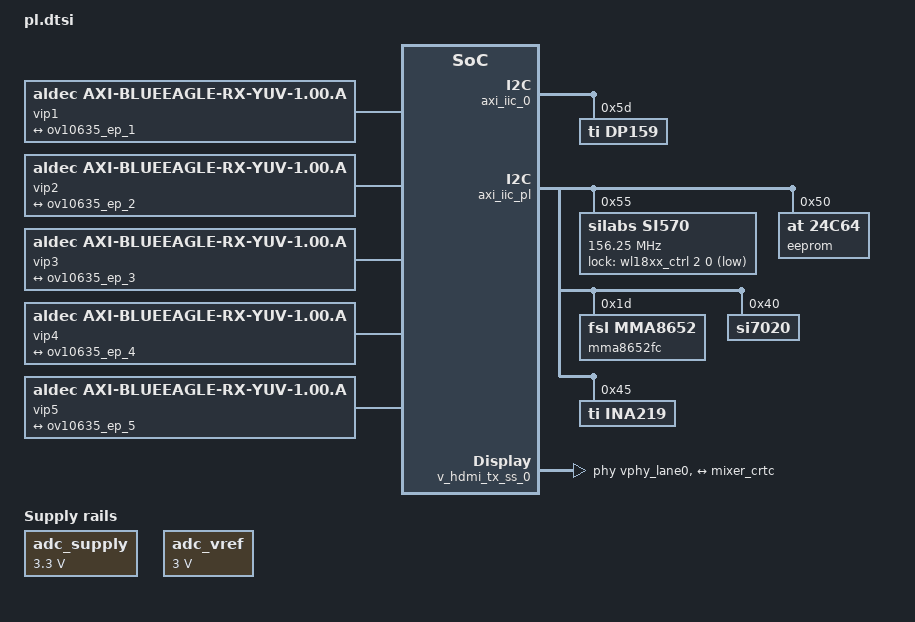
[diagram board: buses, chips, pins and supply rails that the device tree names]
/*
 * CAUTION: This file is automatically generated by Xilinx.
 * Version: XSCT 2018.3
 * Today is: Fri Feb  1 14:32:24 2019
 */


/ {
	amba_pl: amba_pl@0 {
		#address-cells = <2>;
		#size-cells = <2>;
		compatible = "simple-bus";
		ranges ;
		axi_gpio_des: gpio@a0001000 {
			#gpio-cells = <3>;
			clock-names = "s_axi_aclk";
			clocks = <&misc_clk_0>;
			compatible = "xlnx,axi-gpio-2.0", "xlnx,xps-gpio-1.00.a";
			gpio-controller ;
			reg = <0x0 0xa0001000 0x0 0x1000>;
			xlnx,all-inputs = <0x0>;
			xlnx,all-inputs-2 = <0x0>;
			xlnx,all-outputs = <0x1>;
			xlnx,all-outputs-2 = <0x0>;
			xlnx,dout-default = <0x0000000E>;
			xlnx,dout-default-2 = <0x00000000>;
			xlnx,gpio-width = <0x4>;
			xlnx,gpio2-width = <0x20>;
			xlnx,interrupt-present = <0x0>;
			xlnx,is-dual = <0x0>;
			xlnx,tri-default = <0xFFFFFFFF>;
			xlnx,tri-default-2 = <0xFFFFFFFF>;
		};        
		gpio-pdb {
		    compatible = "linux,gpio-reset";

		    multides {
		        // Put PDB line low for a 1 ms during bootup
		        gpios = <&axi_gpio_des 1 0 0>;
		        asserted-state = <0>;
		        duration-ms = <1>;
		        auto;
		    };
		};
		axi_gpio_ov_ctrl: gpio@a0004000 {
			#gpio-cells = <3>;
			clock-names = "s_axi_aclk";
			clocks = <&misc_clk_0>;
			compatible = "xlnx,axi-gpio-2.0", "xlnx,xps-gpio-1.00.a";
			gpio-controller ;
			reg = <0x0 0xa0004000 0x0 0x1000>;
			xlnx,all-inputs = <0x0>;
			xlnx,all-inputs-2 = <0x0>;
			xlnx,all-outputs = <0x1>;
			xlnx,all-outputs-2 = <0x0>;
			xlnx,dout-default = <0x00000155>;
			xlnx,dout-default-2 = <0x00000000>;
			xlnx,gpio-width = <0xa>;
			xlnx,gpio2-width = <0x20>;
			xlnx,interrupt-present = <0x0>;
			xlnx,is-dual = <0x0>;
			xlnx,tri-default = <0xFFFFFFFF>;
			xlnx,tri-default-2 = <0xFFFFFFFF>;
		};
		axi_iic_0: i2c@a000b000 {
			#address-cells = <1>;
			#size-cells = <0>;
			clock-names = "s_axi_aclk";
			clocks = <&misc_clk_0>;
			compatible = "xlnx,axi-iic-2.0", "xlnx,xps-iic-2.00.a";
			interrupt-names = "iic2intc_irpt";
			interrupt-parent = <&axi_intc_0>;
			interrupts = <9 2>;
			reg = <0x0 0xa000b000 0x0 0x1000>;
			dp159: hdmi-retimer@5d {
					status = "okay";
					compatible = "ti,dp159";
					reg = <0x5d>;
					#address-cells = <1>;
					#size-cells = <0>;
					#clock-cells = <0>;
				};
		};
		axi_iic_pl: i2c@a0003000 {
			#address-cells = <1>;
			#size-cells = <0>;
			clock-names = "s_axi_aclk";
			clocks = <&misc_clk_0>;
			compatible = "xlnx,axi-iic-2.0", "xlnx,xps-iic-2.00.a";
			interrupt-names = "iic2intc_irpt";
			interrupt-parent = <&axi_intc_0>;
			interrupts = <0 2>;
			reg = <0x0 0xa0003000 0x0 0x1000>;
			
			si570: clock-generator@55 {
				#clock-cells = <0>;
				compatible = "silabs,si570";
				reg = <0x55>;
				temperature-stability = <50>;
				factory-fout = <156250000>;
				clock-frequency = <156250000>;
				lock-gpios = <&wl18xx_ctrl 2 0 1>;
			};
				
			
			eeprom@50 {
				compatible = "at,24c64";
				reg = <0x50>;
			};
			
			/* DNI */
			mma8652fc@1d {
				compatible = "fsl,mma8652";
				reg = <0x1d>;
			};
			
			si7020@40 {
				compatible = "si7020";
				reg = <0x40>;
			};
			
			ina219@45 {
				compatible = "ti,ina219";
				reg = <0x45>;
				shunt-resistor = <2000>;
			};
		};
		axi_intc_0: interrupt-controller@a000a000 {
			#interrupt-cells = <2>;
			compatible = "xlnx,axi-intc-4.1", "xlnx,xps-intc-1.00.a";
			interrupt-controller ;
			interrupt-names = "irq";
			interrupt-parent = <&gic>;
			interrupts = <0 89 4>;
			reg = <0x0 0xa000a000 0x0 0x1000>;
			xlnx,kind-of-intr = <0x0>;
			xlnx,num-intr-inputs = <0xa>;
		};
		
		adc_supply: fixedregulator-vcc {
			compatible = "regulator-fixed";
			regulator-name = "fixed-supply";
			regulator-min-microvolt = <3300000>;
			regulator-max-microvolt = <3300000>;
		};

		adc_vref: fixedregulator-refin {
			compatible = "regulator-fixed";
			regulator-name = "fixed-supply";
			regulator-min-microvolt = <3000000>;
			regulator-max-microvolt = <3000000>;
		};
		axi_timer_0: timer@a0009000 {
			clock-frequency = <50000000>;
			clock-names = "s_axi_aclk";
			clocks = <&misc_clk_0>;
			#pwm-cells = <1>;
			compatible = "xlnx,axi-timer-2.0";
			xlnx,pwm-outputs = <1>;
			reg = <0x0 0xa0009000 0x0 0x1000>;
			xlnx,count-width = <0x20>;
			xlnx,gen0-assert = <0x1>;
			xlnx,gen1-assert = <0x1>;
			xlnx,one-timer-only = <0x0>;
			xlnx,trig0-assert = <0x1>;
			xlnx,trig1-assert = <0x1>;
		};
		nidru: nidru {
			compatible = "fixed-clock";
			#clock-cells = <0x0>;
			clock-frequency = <156250000>;
		};
		psu_ctrl_ipi: PERIPHERAL@ff380000 {
			/* This is a place holder node for a custom IP, user may need to update the entries */
			compatible = "xlnx,PERIPHERAL-1.0";
			reg = <0x0 0xff380000 0x0 0x80000>;
		};
		psu_message_buffers: PERIPHERAL@ff990000 {
			/* This is a place holder node for a custom IP, user may need to update the entries */
			compatible = "xlnx,PERIPHERAL-1.0";
			reg = <0x0 0xff990000 0x0 0x10000>;
		};
		v_hdmi_tx_ss_0: v_hdmi_tx_ss@a0020000 {
			/* This is a place holder node for a custom IP, user may need to update the entries */
			compatible = "xlnx,v-hdmi-tx-ss-3.1";

			interrupt-names = "irq";
			interrupt-parent = <&axi_intc_0>;
			interrupts = <7 2>;

			reg = <0x0 0xa0020000 0x0 0x20000>;

			clocks = <&misc_clk_0>, <&misc_clk_1>, <&si570>, <&dp159>;
			clock-names = "axi-lite", "video", "txref-clk", "retimer-clk";

			phy-names = "hdmi-phy0", "hdmi-phy1", "hdmi-phy2";
			phys = <&vphy_lane0 0 1 1 1>, <&vphy_lane1 0 1 1 1>, <&vphy_lane2 0 1 1 1>;

			/*xlnx,add-mark-dbg = "false";
			xlnx,addr-width = <0xa>;
			xlnx,exdes-axilite-freq = <0x64>;
			xlnx,exdes-nidru = "false";
			xlnx,exdes-rx-pll-selection = <0x0>;
			xlnx,exdes-topology = <0x1>;
			xlnx,exdes-tx-pll-selection = <0x6>;
			xlnx,hdmi-fast-switch = "false";
			xlnx,hdmi-version = <0x3>;
			xlnx,hpd-invert = "false";
			xlnx,hysteresis-level = <0xc>;
			xlnx,include-hdcp-1-4 = "false";
			xlnx,include-hdcp-2-2 = "false";
			xlnx,include-low-reso-vid = "false";
			xlnx,include-yuv420-sup = "true";
			xlnx,input-pixels-per-clock = <0x2>;
			xlnx,max-bits-per-component = <0x8>;
			xlnx,validation-enable = "false";
			xlnx,vid-interface = <0x0>;
			xlnx,video-mask-enable = <0x1>;*/

			xlnx,output-fmt = "rgb";
			xlnx,input-pixels-per-clock = <0x2>;
			xlnx,max-bits-per-component = <0x8>;
			
			ports {
				#address-cells = <1>;
				#size-cells = <0>;
				encoder_hdmi_port: port@0 {
					reg = <0>;
					hdmi_encoder: endpoint {
						remote-endpoint = <&mixer_crtc>;
					};
				};
			};
		};
		v_mix_0: v_mix@b0010000 {
			/* This is a place holder node for a custom IP, user may need to update the entries */
			compatible = "xlnx,v-mix-3.0", "xlnx,mixer-3.0";
			interrupt-names = "interrupt";
			interrupt-parent = <&axi_intc_0>;
			interrupts = <6 2>;
			reg = <0x0 0xb0010000 0x0 0x10000>;
			xlnx,s-axi-ctrl-addr-width = <0xc>;
			xlnx,s-axi-ctrl-data-width = <0x20>;
			reset-gpios = <&gpio 79 1>;
			clocks = <&si570>;
			xlnx,connector-type = "HDMIA";
			xlnx,dma-addr-width=<32>;

			xlnx,bpc = <8>;
			xlnx,ppc = <2>;
			xlnx,num-layers = <5>;

			crtc_mixer_port: port@0 {
					reg = <0>;
					mixer_crtc: endpoint {
					remote-endpoint = <&hdmi_encoder>;
				};
			};

			mixer_master_layer: layer_0 {
				xlnx,layer-id = <0>;
				xlnx,layer-max-width = <3840>;
				xlnx,layer-max-height = <2160>;
				xlnx,vformat = "BG24";
			};
			mixer_overlay_1: layer_1 {
				xlnx,layer-id = <1>;
				xlnx,vformat = "YUYV";
				xlnx,layer-alpha;
				xlnx,layer-max-width = <3840>;
			};
			mixer_overlay_2: layer_2 {
				xlnx,layer-id = <2>;
				xlnx,vformat = "YUYV";
				xlnx,layer-alpha;
				xlnx,layer-max-width = <3840>;
			};
			mixer_overlay_3: layer_3 {
				xlnx,layer-id = <3>;
				xlnx,vformat = "UYVY";
				xlnx,layer-alpha;
				xlnx,layer-max-width = <3840>;
			};
			mixer_overlay_4: layer_4 {
				xlnx,layer-id = <4>;
				xlnx,vformat = "AR24";
				xlnx,layer-alpha;
				xlnx,layer-max-width = <3840>;
				xlnx,layer-primary;
			};
			xv_mix_logo: logo {
				xlnx,layer-id = <5>;
				xlnx,logo-height = <64>;
				xlnx,logo-width = <64>;
			};
		};
		vid_phy_controller_0: vid_phy_controller@a0060000 {
			/* This is a place holder node for a custom IP, user may need to update the entries */
			compatible = "xlnx,vid-phy-controller-2.2";
			interrupt-names = "irq";
			interrupt-parent = <&axi_intc_0>;
			interrupts = <8 2>;
			reg = <0x0 0xa0060000 0x0 0x10000>;
			clocks = <&misc_clk_0>, <&nidru>;
			clock-names = "axi-lite", "dru-clk";
			xlnx,axi4lite-enable = "true";
			xlnx,component-name = "TySOM_3_ZU7_FMC1_FMC_ADAS_vid_phy_controller_0_0";
			xlnx,device = "xczu7ev";
			xlnx,dru-gain-g1 = <0x9>;
			xlnx,dru-gain-g1-p = <0x10>;
			xlnx,dru-gain-g2 = <0x4>;
			xlnx,dru-refclk-fabric-buffer = "none";
			xlnx,err-irq-en = <0x0>;
			xlnx,for-upgrade-architecture = "placeholder";
			xlnx,for-upgrade-device = "placeholder";
			xlnx,for-upgrade-maxoptvol = "0.00";
			xlnx,for-upgrade-package = "placeholder";
			xlnx,for-upgrade-part = "placeholder";
			xlnx,for-upgrade-refvol = "0.00";
			xlnx,for-upgrade-speedgrade = <0x0>;
			xlnx,hdmi-fast-switch = <0x1>;
			xlnx,input-pixels-per-clock = <0x2>;
			xlnx,int-hdmi-ver-cmptble = <0x3>;
			xlnx,nidru = <0x0>;
			xlnx,nidru-refclk-sel = <0x0>;
			xlnx,rx-gt-debug-ports = "false";
			xlnx,rx-no-of-channels = <0x3>;
			xlnx,rx-outclk-buffer = "none";
			xlnx,rx-pll-selection = <0x0>;
			xlnx,rx-protocol = <0x3>;
			xlnx,rx-raw-mode-en = "false";
			xlnx,rx-refclk-sel = <0x1>;
			xlnx,rx-sb-ports = "true";
			xlnx,rx-tmds-clk-buffer = "bufg";
			xlnx,rx-video-clk-buffer = "bufg";
			xlnx,silicon-revision = <0x0>;
			xlnx,speedgrade = "-2";
			xlnx,supportlevel = <0x1>;
			xlnx,transceivercontrol = "false";
			xlnx,tx-gt-debug-ports = "false";
			xlnx,tx-no-of-channels = <0x3>;
			xlnx,tx-outclk-buffer = "none";
			xlnx,tx-pll-selection = <0x6>;
			xlnx,tx-protocol = <0x1>;
			xlnx,tx-raw-mode-en = "false";
			xlnx,tx-refclk-fabric-buffer = "none";
			xlnx,tx-refclk-sel = <0x0>;
			xlnx,tx-sb-ports = "true";
			xlnx,tx-tmds-clk-buffer = "bufg";
			xlnx,tx-video-clk-buffer = "bufg";
			xlnx,txpi-port-en = "false";
			xlnx,txrefclk-rdy-invert = <0x1>;
			xlnx,use-gt-ch4-hdmi = <0x0>;
			xlnx,use-oddr-for-tmds-clkout = "true";
			xlnx,vid-phy-axi4lite-addr-width = <0xa>;
			xlnx,vid-phy-axi4lite-data-width = <0x20>;
			xlnx,vid-phy-control-sb-rx-tdata-width = <0x1>;
			xlnx,vid-phy-control-sb-tx-tdata-width = <0x1>;
			xlnx,vid-phy-rx-axi4s-ch-int-tdata-width = <0x14>;
			xlnx,vid-phy-rx-axi4s-ch-tdata-width = <0x14>;
			xlnx,vid-phy-rx-axi4s-ch-tuser-width = <0x1>;
			xlnx,vid-phy-status-sb-rx-tdata-width = <0x1>;
			xlnx,vid-phy-status-sb-tx-tdata-width = <0x2>;
			xlnx,vid-phy-tx-axi4s-ch-int-tdata-width = <0x14>;
			xlnx,vid-phy-tx-axi4s-ch-tdata-width = <0x14>;
			xlnx,vid-phy-tx-axi4s-ch-tuser-width = <0x1>;
			xlnx,viper-reg = "false";
			xlnx,transceiver-type = <0x5>;
			xlnx,tx-buffer-bypass = <0x1>;
			xlnx,transceiver-width = <2>;
			vphy_lane0: vphy_lane@0 {
				#phy-cells = <4>;
			};
			vphy_lane1: vphy_lane@1 {
				#phy-cells = <4>;
			};
			vphy_lane2: vphy_lane@2 {
				#phy-cells = <4>;
			};
			vphy_lane3: vphy_lane@3 {
				#phy-cells = <4>;
			};
		};
		vip1_axi_vdma_des1: dma@a0000000 {
			#dma-cells = <1>;
			clock-names = "s_axi_lite_aclk", "m_axi_s2mm_aclk", "s_axis_s2mm_aclk";
			clocks = <&misc_clk_0>, <&misc_clk_0>, <&misc_clk_0>;
			compatible = "xlnx,axi-vdma-6.3", "xlnx,axi-vdma-1.00.a";
			interrupt-names = "s2mm_introut";
			interrupt-parent = <&axi_intc_0>;
			interrupts = <1 2>;
			reg = <0x0 0xa0000000 0x0 0x1000>;
			xlnx,addrwidth = <0x20>;
			xlnx,flush-fsync = <0x1>;
			xlnx,num-fstores = <0x3>;
			dma-channel@a0000030 {
				compatible = "xlnx,axi-vdma-s2mm-channel";
				interrupts = <1 2>;
				xlnx,datawidth = <0x10>;
				xlnx,device-id = <0x0>;
				xlnx,genlock-mode ;
			};
		};
		vip2_axi_vdma_des2: dma@a0005000 {
			#dma-cells = <1>;
			clock-names = "s_axi_lite_aclk", "m_axi_s2mm_aclk", "s_axis_s2mm_aclk";
			clocks = <&misc_clk_0>, <&misc_clk_0>, <&misc_clk_0>;
			compatible = "xlnx,axi-vdma-6.3", "xlnx,axi-vdma-1.00.a";
			interrupt-names = "s2mm_introut";
			interrupt-parent = <&axi_intc_0>;
			interrupts = <2 2>;
			reg = <0x0 0xa0005000 0x0 0x1000>;
			xlnx,addrwidth = <0x20>;
			xlnx,flush-fsync = <0x1>;
			xlnx,num-fstores = <0x3>;
			dma-channel@a0005030 {
				compatible = "xlnx,axi-vdma-s2mm-channel";
				interrupts = <2 2>;
				xlnx,datawidth = <0x10>;
				xlnx,device-id = <0x1>;
				xlnx,genlock-mode ;
			};
		};
		vip3_axi_vdma_des3: dma@a0006000 {
			#dma-cells = <1>;
			clock-names = "s_axi_lite_aclk", "m_axi_s2mm_aclk", "s_axis_s2mm_aclk";
			clocks = <&misc_clk_0>, <&misc_clk_0>, <&misc_clk_0>;
			compatible = "xlnx,axi-vdma-6.3", "xlnx,axi-vdma-1.00.a";
			interrupt-names = "s2mm_introut";
			interrupt-parent = <&axi_intc_0>;
			interrupts = <3 2>;
			reg = <0x0 0xa0006000 0x0 0x1000>;
			xlnx,addrwidth = <0x20>;
			xlnx,flush-fsync = <0x1>;
			xlnx,num-fstores = <0x3>;
			dma-channel@a0006030 {
				compatible = "xlnx,axi-vdma-s2mm-channel";
				interrupts = <3 2>;
				xlnx,datawidth = <0x10>;
				xlnx,device-id = <0x2>;
				xlnx,genlock-mode ;
			};
		};
		vip4_axi_vdma_des4: dma@a0007000 {
			#dma-cells = <1>;
			clock-names = "s_axi_lite_aclk", "m_axi_s2mm_aclk", "s_axis_s2mm_aclk";
			clocks = <&misc_clk_0>, <&misc_clk_0>, <&misc_clk_0>;
			compatible = "xlnx,axi-vdma-6.3", "xlnx,axi-vdma-1.00.a";
			interrupt-names = "s2mm_introut";
			interrupt-parent = <&axi_intc_0>;
			interrupts = <4 2>;
			reg = <0x0 0xa0007000 0x0 0x1000>;
			xlnx,addrwidth = <0x20>;
			xlnx,flush-fsync = <0x1>;
			xlnx,num-fstores = <0x3>;
			dma-channel@a0007030 {
				compatible = "xlnx,axi-vdma-s2mm-channel";
				interrupts = <4 2>;
				xlnx,datawidth = <0x10>;
				xlnx,device-id = <0x3>;
				xlnx,genlock-mode ;
			};
		};
		vip5_axi_vdma_des5: dma@a0008000 {
			#dma-cells = <1>;
			clock-names = "s_axi_lite_aclk", "m_axi_s2mm_aclk", "s_axis_s2mm_aclk";
			clocks = <&misc_clk_0>, <&misc_clk_0>, <&misc_clk_0>;
			compatible = "xlnx,axi-vdma-6.3", "xlnx,axi-vdma-1.00.a";
			interrupt-names = "s2mm_introut";
			interrupt-parent = <&axi_intc_0>;
			interrupts = <5 2>;
			reg = <0x0 0xa0008000 0x0 0x1000>;
			xlnx,addrwidth = <0x20>;
			xlnx,flush-fsync = <0x1>;
			xlnx,num-fstores = <0x3>;
			dma-channel@a0008030 {
				compatible = "xlnx,axi-vdma-s2mm-channel";
				interrupts = <5 2>;
				xlnx,datawidth = <0x10>;
				xlnx,device-id = <0x4>;
				xlnx,genlock-mode ;
			};
		};
		
		vip1 {
			compatible = "aldec,axi-blueeagle-rx-yuv-1.00.a";

			dmas = <&vip1_axi_vdma_des1 0>;
			dma-names = "video";

			port {
				vip_ep_1: endpoint {
					remote-endpoint = <&ov10635_ep_1>;
				};
			};
		};
		
		vip2 {
			compatible = "aldec,axi-blueeagle-rx-yuv-1.00.a";

			dmas = <&vip2_axi_vdma_des2 0>;
			dma-names = "video";

			port {
				vip_ep_2: endpoint {
					remote-endpoint = <&ov10635_ep_2>;
				};
			};
		};
		
		vip3 {
			compatible = "aldec,axi-blueeagle-rx-yuv-1.00.a";

			dmas = <&vip3_axi_vdma_des3 0>;
			dma-names = "video";

			port {
				vip_ep_3: endpoint {
					remote-endpoint = <&ov10635_ep_3>;
				};
			};
		};
		
		vip4 {
			compatible = "aldec,axi-blueeagle-rx-yuv-1.00.a";

			dmas = <&vip4_axi_vdma_des4 0>;
			dma-names = "video";

			port {
				vip_ep_4: endpoint {
					remote-endpoint = <&ov10635_ep_4>;
				};
			};
		};
		
		vip5 {
			compatible = "aldec,axi-blueeagle-rx-yuv-1.00.a";

			dmas = <&vip5_axi_vdma_des5 0>;
			dma-names = "video";

			port {
				vip_ep_5: endpoint {
					remote-endpoint = <&ov10635_ep_5>;
				};
			};
		};
		wl18xx_ctrl: gpio@a0002000 {
			#gpio-cells = <3>;
			clock-names = "s_axi_aclk";
			clocks = <&misc_clk_0>;
			compatible = "xlnx,axi-gpio-2.0", "xlnx,xps-gpio-1.00.a";
			gpio-controller ;
			reg = <0x0 0xa0002000 0x0 0x1000>;
			xlnx,all-inputs = <0x0>;
			xlnx,all-inputs-2 = <0x0>;
			xlnx,all-outputs = <0x1>;
			xlnx,all-outputs-2 = <0x0>;
			xlnx,dout-default = <0x00000000>;
			xlnx,dout-default-2 = <0x00000000>;
			xlnx,gpio-width = <0x3>;
			xlnx,gpio2-width = <0x20>;
			xlnx,interrupt-present = <0x0>;
			xlnx,is-dual = <0x0>;
			xlnx,tri-default = <0xFFFFFFFF>;
			xlnx,tri-default-2 = <0xFFFFFFFF>;
		};
		misc_clk_0: misc_clk_0 {
			#clock-cells = <0>;
			clock-frequency = <50000000>;
			compatible = "fixed-clock";
		};
		misc_clk_1: misc_clk_1 {
			#clock-cells = <0>;
			clock-frequency = <150000000>;
			compatible = "fixed-clock";
		};
	};
};
&sata {
	ceva,p0-burst-params = /bits/ 8 <0x13 0x08 0x4A 0x06>;
	ceva,p0-cominit-params = /bits/ 8 <0x18 0x40 0x18 0x28>;
	ceva,p0-comwake-params = /bits/ 8 <0x06 0x14 0x08 0x0E>;
	ceva,p0-retry-params = /bits/ 16 <0x96A4 0x3FFC>;
	ceva,p1-burst-params = /bits/ 8 <0x13 0x08 0x4A 0x06>;
	ceva,p1-cominit-params = /bits/ 8 <0x18 0x40 0x18 0x28>;
	ceva,p1-comwake-params = /bits/ 8 <0x06 0x14 0x08 0x0E>;
	ceva,p1-retry-params = /bits/ 16 <0x96A4 0x3FFC>;
};
